VERSION ""

NS_ :

BS_:

BU_:

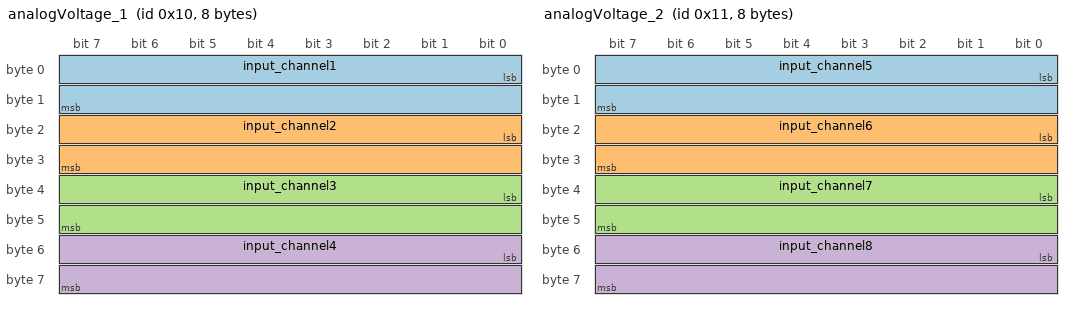
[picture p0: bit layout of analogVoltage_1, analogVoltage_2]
BO_ 16 analogVoltage_1: 8 Vector__XXX
 SG_ input_channel1 : 0|16@1+ (1,0) [0|65535] "mV" Vector__XXX
 SG_ input_channel2 : 16|16@1+ (1,0) [0|65535] "mV" Vector__XXX
 SG_ input_channel3 : 32|16@1+ (1,0) [0|65535] "mV" Vector__XXX
 SG_ input_channel4 : 48|16@1+ (1,0) [0|65535] "mV" Vector__XXX

BO_ 17 analogVoltage_2: 8 Vector__XXX
 SG_ input_channel5 : 0|16@1+ (1,0) [0|65535] "mV" Vector__XXX
 SG_ input_channel6 : 16|16@1+ (1,0) [0|65535] "mV" Vector__XXX
 SG_ input_channel7 : 32|16@1+ (1,0) [0|65535] "mV" Vector__XXX
 SG_ input_channel8 : 48|16@1+ (1,0) [0|65535] "mV" Vector__XXX

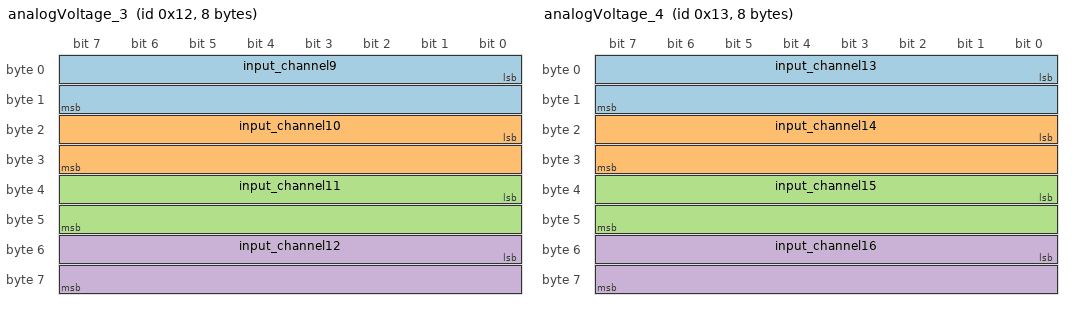
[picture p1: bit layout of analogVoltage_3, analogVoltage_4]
BO_ 18 analogVoltage_3: 8 Vector__XXX
 SG_ input_channel9 : 0|16@1+ (1,0) [0|65535] "mV" Vector__XXX
 SG_ input_channel10 : 16|16@1+ (1,0) [0|65535] "mV" Vector__XXX
 SG_ input_channel11 : 32|16@1+ (1,0) [0|65535] "mV" Vector__XXX
 SG_ input_channel12 : 48|16@1+ (1,0) [0|65535] "mV" Vector__XXX

BO_ 19 analogVoltage_4: 8 Vector__XXX
 SG_ input_channel13 : 0|16@1+ (1,0) [0|65535] "mV" Vector__XXX
 SG_ input_channel14 : 16|16@1+ (1,0) [0|65535] "mV" Vector__XXX
 SG_ input_channel15 : 32|16@1+ (1,0) [0|65535] "mV" Vector__XXX
 SG_ input_channel16 : 48|16@1+ (1,0) [0|65535] "mV" Vector__XXX

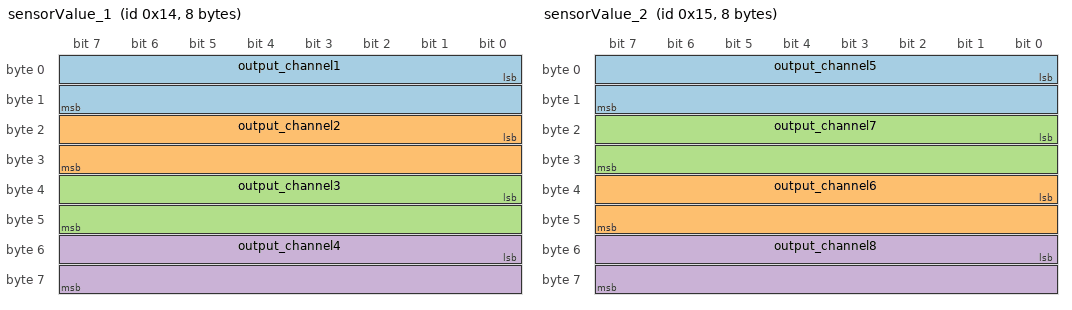
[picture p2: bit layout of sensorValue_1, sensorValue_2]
BO_ 20 sensorValue_1: 8 Vector__XXX
 SG_ output_channel1 : 0|16@1+ (0.01,0) [0|0] "" Vector__XXX
 SG_ output_channel2 : 16|16@1+ (0.01,0) [0|0] "" Vector__XXX
 SG_ output_channel3 : 32|16@1- (1,0) [0|0] "C" Vector__XXX
 SG_ output_channel4 : 48|16@1+ (0.01,0) [0|0] "" Vector__XXX

BO_ 21 sensorValue_2: 8 Vector__XXX
 SG_ output_channel5 : 0|16@1+ (0.01,0) [0|0] "" Vector__XXX
 SG_ output_channel6 : 32|16@1- (1,0) [0|0] "C" Vector__XXX
 SG_ output_channel7 : 16|16@1+ (0.01,0) [0|0] "" Vector__XXX
 SG_ output_channel8 : 48|16@1+ (0.01,0) [0|0] "" Vector__XXX

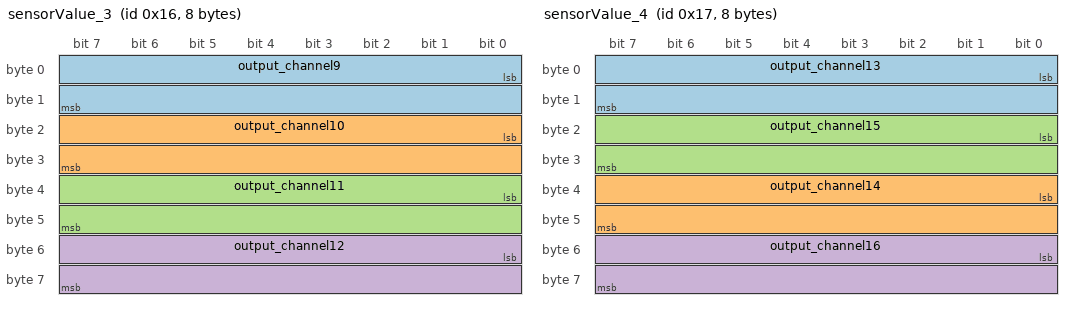
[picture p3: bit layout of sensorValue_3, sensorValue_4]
BO_ 22 sensorValue_3: 8 Vector__XXX
 SG_ output_channel9 : 0|16@1+ (0.01,0) [0|0] "" Vector__XXX
 SG_ output_channel10 : 16|16@1+ (0.01,0) [0|0] "" Vector__XXX
 SG_ output_channel11 : 32|16@1- (1,0) [0|0] "C" Vector__XXX
 SG_ output_channel12 : 48|16@1+ (0.01,0) [0|0] "" Vector__XXX

BO_ 23 sensorValue_4: 8 Vector__XXX
 SG_ output_channel13 : 0|16@1+ (0.01,0) [0|0] "" Vector__XXX
 SG_ output_channel14 : 32|16@1- (1,0) [0|0] "C" Vector__XXX
 SG_ output_channel15 : 16|16@1+ (0.01,0) [0|0] "" Vector__XXX
 SG_ output_channel16 : 48|16@1+ (0.01,0) [0|0] "" Vector__XXX
